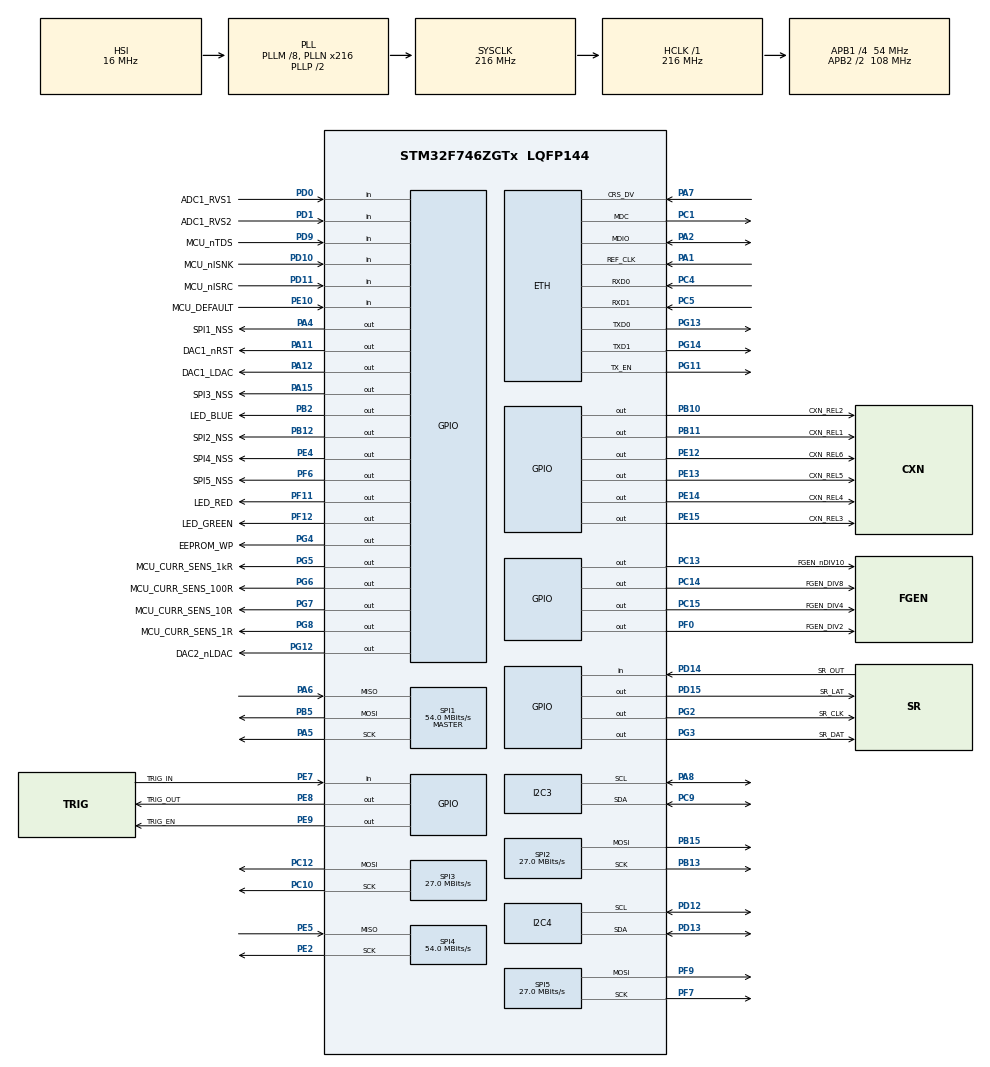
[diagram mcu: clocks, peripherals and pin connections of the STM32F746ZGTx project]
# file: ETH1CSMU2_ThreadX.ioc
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CORTEX_M7.CPU_DCache=Enabled
CORTEX_M7.CPU_ICache=Enabled
Dma.Request0=SPI4_RX
Dma.SPI4_RX.0.Direction=DMA_PERIPH_TO_MEMORY
Dma.SPI4_RX.0.FIFOMode=DMA_FIFOMODE_DISABLE
Dma.SPI4_RX.0.Instance=DMA2_Stream0
Dma.SPI4_RX.0.MemDataAlignment=DMA_MDATAALIGN_HALFWORD
Dma.SPI4_RX.0.MemInc=DMA_MINC_ENABLE
Dma.SPI4_RX.0.Mode=DMA_NORMAL
Dma.SPI4_RX.0.PeriphDataAlignment=DMA_PDATAALIGN_HALFWORD
Dma.SPI4_RX.0.PeriphInc=DMA_PINC_DISABLE
Dma.SPI4_RX.0.Priority=DMA_PRIORITY_LOW
ETH.MediaInterface=HAL_ETH_RMII_MODE
ETH.RxMode=ETH_RXINTERRUPT_MODE
I2C3.Timing=0x20404768
I2C4.Timing=0x20404768
Mcu.Family=STM32F7
Mcu.Name=STM32F746ZGTx
Mcu.Package=LQFP144
NVIC.DMA2_Stream0_IRQn=true\:0\:0\:false\:false\:true\:true\:false\:true\:true
NVIC.ETH_IRQn=true\:7\:0\:true\:false\:true\:false\:true\:true\:true
NVIC.PriorityGroup=NVIC_PRIORITYGROUP_4
NVIC.TIM1_UP_TIM10_IRQn=true\:15\:0\:false\:false\:true\:false\:false\:true\:true
NVIC.TimeBase=TIM1_UP_TIM10_IRQn
NVIC.TimeBaseIP=TIM1
PA1.Mode=RMII
PA1.Signal=ETH_REF_CLK
PA11.GPIO_Label=DAC1_nRST
PA11.PinState=GPIO_PIN_SET
PA11.Signal=GPIO_Output
PA12.GPIO_Label=DAC1_LDAC
PA12.Signal=GPIO_Output
PA13.Mode=Serial_Wire
PA13.Signal=SYS_JTMS-SWDIO
PA14.Mode=Serial_Wire
PA14.Signal=SYS_JTCK-SWCLK
PA15.GPIO_Label=SPI3_NSS
PA15.GPIO_Speed=GPIO_SPEED_FREQ_HIGH
PA15.PinState=GPIO_PIN_SET
PA15.Signal=GPIO_Output
PA2.Mode=RMII
PA2.Signal=ETH_MDIO
PA4.GPIO_Label=SPI1_NSS
PA4.GPIO_Speed=GPIO_SPEED_FREQ_HIGH
PA4.PinState=GPIO_PIN_SET
PA4.Signal=GPIO_Output
PA5.GPIO_Speed=GPIO_SPEED_FREQ_HIGH
PA5.Mode=Full_Duplex_Master
PA5.Signal=SPI1_SCK
PA6.GPIO_Speed=GPIO_SPEED_FREQ_HIGH
PA6.Mode=Full_Duplex_Master
PA6.Signal=SPI1_MISO
PA7.Mode=RMII
PA7.Signal=ETH_CRS_DV
PA8.Mode=I2C
PA8.Signal=I2C3_SCL
PB10.GPIO_Label=CXN_REL2
PB10.GPIO_Speed=GPIO_SPEED_FREQ_HIGH
PB10.Signal=GPIO_Output
PB11.GPIO_Label=CXN_REL1
PB11.GPIO_Speed=GPIO_SPEED_FREQ_HIGH
PB11.Signal=GPIO_Output
PB12.GPIO_Label=SPI2_NSS
PB12.GPIO_Speed=GPIO_SPEED_FREQ_HIGH
PB12.PinState=GPIO_PIN_SET
PB12.Signal=GPIO_Output
PB13.Mode=TX_Only_Simplex_Unidirect_Master
PB13.Signal=SPI2_SCK
PB15.Mode=TX_Only_Simplex_Unidirect_Master
PB15.Signal=SPI2_MOSI
PB2.GPIO_Label=LED_BLUE
PB2.PinState=GPIO_PIN_SET
PB2.Signal=GPIO_Output
PB5.GPIO_Speed=GPIO_SPEED_FREQ_HIGH
PB5.Mode=Full_Duplex_Master
PB5.Signal=SPI1_MOSI
PC1.Mode=RMII
PC1.Signal=ETH_MDC
PC10.GPIO_PuPd=GPIO_PULLUP
PC10.GPIO_Speed=GPIO_SPEED_FREQ_HIGH
PC10.Mode=TX_Only_Simplex_Unidirect_Master
PC10.Signal=SPI3_SCK
PC12.GPIO_PuPd=GPIO_NOPULL
PC12.GPIO_Speed=GPIO_SPEED_FREQ_HIGH
PC12.Mode=TX_Only_Simplex_Unidirect_Master
PC12.Signal=SPI3_MOSI
PC13.GPIO_Label=FGEN_nDIV10
PC13.PinState=GPIO_PIN_SET
PC13.Signal=GPIO_Output
PC14/OSC32_IN.GPIO_Label=FGEN_DIV8
PC14/OSC32_IN.PinState=GPIO_PIN_SET
PC14/OSC32_IN.Signal=GPIO_Output
PC15/OSC32_OUT.GPIO_Label=FGEN_DIV4
PC15/OSC32_OUT.PinState=GPIO_PIN_SET
PC15/OSC32_OUT.Signal=GPIO_Output
PC4.Mode=RMII
PC4.Signal=ETH_RXD0
PC5.Mode=RMII
PC5.Signal=ETH_RXD1
PC9.Mode=I2C
PC9.Signal=I2C3_SDA
PD0.GPIO_Label=ADC1_RVS1
PD0.Signal=GPIO_Input
PD1.GPIO_Label=ADC1_RVS2
PD1.Signal=GPIO_Input
PD10.GPIO_Label=MCU_nISNK
PD10.Signal=GPIO_Input
PD11.GPIO_Label=MCU_nISRC
PD11.Signal=GPIO_Input
PD12.Mode=I2C
PD12.Signal=I2C4_SCL
PD13.Mode=I2C
PD13.Signal=I2C4_SDA
PD14.GPIO_Label=SR_OUT
PD14.Signal=GPIO_Input
PD15.GPIO_Label=SR_LAT
PD15.Signal=GPIO_Output
PD9.GPIO_Label=MCU_nTDS
PD9.Signal=GPIO_Input
PE10.GPIO_Label=MCU_DEFAULT
PE10.Signal=GPIO_Input
PE12.GPIO_Label=CXN_REL6
PE12.GPIO_Speed=GPIO_SPEED_FREQ_HIGH
PE12.Signal=GPIO_Output
PE13.GPIO_Label=CXN_REL5
PE13.GPIO_Speed=GPIO_SPEED_FREQ_HIGH
PE13.Signal=GPIO_Output
PE14.GPIO_Label=CXN_REL4
PE14.GPIO_Speed=GPIO_SPEED_FREQ_HIGH
PE14.Signal=GPIO_Output
PE15.GPIO_Label=CXN_REL3
PE15.GPIO_Speed=GPIO_SPEED_FREQ_HIGH
PE15.Signal=GPIO_Output
PE2.Mode=RX_Only_Simplex_Unidirect_Master
PE2.Signal=SPI4_SCK
PE4.GPIO_Label=SPI4_NSS
PE4.Signal=GPIO_Output
PE5.Mode=RX_Only_Simplex_Unidirect_Master
PE5.Signal=SPI4_MISO
PE7.GPIO_Label=TRIG_IN
PE7.Signal=GPIO_Input
PE8.GPIO_Label=TRIG_OUT
PE8.Signal=GPIO_Output
PE9.GPIO_Label=TRIG_EN
PE9.Signal=GPIO_Output
PF0.GPIO_Label=FGEN_DIV2
PF0.PinState=GPIO_PIN_SET
PF0.Signal=GPIO_Output
PF11.GPIO_Label=LED_RED
PF11.PinState=GPIO_PIN_SET
PF11.Signal=GPIO_Output
PF12.GPIO_Label=LED_GREEN
PF12.PinState=GPIO_PIN_SET
PF12.Signal=GPIO_Output
PF6.GPIO_Label=SPI5_NSS
PF6.GPIO_Speed=GPIO_SPEED_FREQ_HIGH
PF6.PinState=GPIO_PIN_SET
PF6.Signal=GPIO_Output
PF7.Mode=TX_Only_Simplex_Unidirect_Master
PF7.Signal=SPI5_SCK
PF9.Mode=TX_Only_Simplex_Unidirect_Master
PF9.Signal=SPI5_MOSI
PG11.Mode=RMII
PG11.Signal=ETH_TX_EN
PG12.GPIO_Label=DAC2_nLDAC
PG12.PinState=GPIO_PIN_SET
PG12.Signal=GPIO_Output
PG13.Mode=RMII
PG13.Signal=ETH_TXD0
PG14.Mode=RMII
PG14.Signal=ETH_TXD1
PG2.GPIO_Label=SR_CLK
PG2.Signal=GPIO_Output
PG3.GPIO_Label=SR_DAT
PG3.Signal=GPIO_Output
PG4.GPIO_Label=EEPROM_WP
PG4.PinState=GPIO_PIN_SET
PG4.Signal=GPIO_Output
PG5.GPIO_Label=MCU_CURR_SENS_1kR
PG5.Signal=GPIO_Output
PG6.GPIO_Label=MCU_CURR_SENS_100R
PG6.PinState=GPIO_PIN_SET
PG6.Signal=GPIO_Output
PG7.GPIO_Label=MCU_CURR_SENS_10R
PG7.Signal=GPIO_Output
PG8.GPIO_Label=MCU_CURR_SENS_1R
PG8.Signal=GPIO_Output
ProjectManager.HeapSize=0x200
ProjectManager.StackSize=0x400
ProjectManager.TargetToolchain=STM32CubeIDE
RCC.AHBFreq_Value=216000000
RCC.APB1CLKDivider=RCC_HCLK_DIV4
RCC.APB1Freq_Value=54000000
RCC.APB1TimFreq_Value=108000000
RCC.APB2CLKDivider=RCC_HCLK_DIV2
RCC.APB2Freq_Value=108000000
RCC.APB2TimFreq_Value=216000000
RCC.CortexFreq_Value=216000000
RCC.HCLKFreq_Value=216000000
RCC.HSE_VALUE=25000000
RCC.HSI_VALUE=16000000
RCC.LSE_VALUE=32768
RCC.PLLM=8
RCC.PLLN=216
RCC.SYSCLKFreq_VALUE=216000000
RCC.SYSCLKSource=RCC_SYSCLKSOURCE_PLLCLK
RCC.USBFreq_Value=216000000
RCC.VCOOutputFreq_Value=432000000
SPI1.CalculateBaudRate=54.0 MBits/s
SPI1.DataSize=SPI_DATASIZE_16BIT
SPI1.Direction=SPI_DIRECTION_2LINES
SPI1.Mode=SPI_MODE_MASTER
SPI1.VirtualType=VM_MASTER
SPI2.CLKPolarity=SPI_POLARITY_HIGH
SPI2.CalculateBaudRate=27.0 MBits/s
SPI2.DataSize=SPI_DATASIZE_8BIT
SPI2.Direction=SPI_DIRECTION_2LINES
SPI2.Mode=SPI_MODE_MASTER
SPI2.VirtualType=VM_MASTER
SPI3.CLKPolarity=SPI_POLARITY_HIGH
SPI3.CalculateBaudRate=27.0 MBits/s
SPI3.DataSize=SPI_DATASIZE_16BIT
SPI3.Direction=SPI_DIRECTION_2LINES
SPI3.Mode=SPI_MODE_MASTER
SPI3.VirtualType=VM_MASTER
SPI4.CalculateBaudRate=54.0 MBits/s
SPI4.DataSize=SPI_DATASIZE_16BIT
SPI4.Direction=SPI_DIRECTION_2LINES_RXONLY
SPI4.Mode=SPI_MODE_MASTER
SPI4.VirtualType=VM_MASTER
SPI5.BaudRatePrescaler=SPI_BAUDRATEPRESCALER_4
SPI5.CalculateBaudRate=27.0 MBits/s
SPI5.DataSize=SPI_DATASIZE_16BIT
SPI5.Direction=SPI_DIRECTION_2LINES
SPI5.Mode=SPI_MODE_MASTER
SPI5.VirtualType=VM_MASTER
STMicroelectronics.X-CUBE-AZRTOS-F7.1.1.0.InterfacesCcNetworkJjEthernetOoInterface=true
STMicroelectronics.X-CUBE-AZRTOS-F7.1.1.0.InterfacesCcNetworkJjEthernetOoPhyOoInterface=LAN8742IiPhyIiInterface
STMicroelectronics.X-CUBE-AZRTOS-F7.1.1.0.NX_APP_MEM_POOL_SIZE=1024*30
STMicroelectronics.X-CUBE-AZRTOS-F7.1.1.0.NetXDuoCcNetworkJjNetXDuoJjAddonsOoAutoIP=true
STMicroelectronics.X-CUBE-AZRTOS-F7.1.1.0.NetXDuoCcNetworkJjNetXDuoJjAddonsOoPPP=true
STMicroelectronics.X-CUBE-AZRTOS-F7.1.1.0.NetXDuoCcNetworkJjNetXDuoJjAddonsOoSNTP=true
STMicroelectronics.X-CUBE-AZRTOS-F7.1.1.0.NetXDuoCcNetworkJjNetXDuoJjNXOoCore=true
STMicroelectronics.X-CUBE-AZRTOS-F7.1.1.0.NetXDuoCcNetworkJjNetXDuoJjTraceXOoSupport=true
STMicroelectronics.X-CUBE-AZRTOS-F7.1.1.0.STM32CubeIiBSPIiComponentsCcBoardOoPartJjETHPhyJjLAN8742=true
STMicroelectronics.X-CUBE-AZRTOS-F7.1.1.0.TX_APP_MEM_POOL_SIZE=1024*2
STMicroelectronics.X-CUBE-AZRTOS-F7.1.1.0.TX_TIMER_TICKS_PER_SECOND=1000
STMicroelectronics.X-CUBE-AZRTOS-F7.1.1.0.ThreadXCcRTOSJjThreadXJjCore=true
STMicroelectronics.X-CUBE-AZRTOS-F7.1.1.0.ThreadXCcRTOSJjThreadXJjLowOoPowerOosupport=true
STMicroelectronics.X-CUBE-AZRTOS-F7.1.1.0.ThreadXCcRTOSJjThreadXJjPerformanceInfo=true
STMicroelectronics.X-CUBE-AZRTOS-F7.1.1.0.ThreadXCcRTOSJjThreadXJjTraceXOosupport=true
STMicroelectronics.X-CUBE-AZRTOS-F7.1.1.0_IsAnAzureRtosMw=true
VP_STMicroelectronics.X-CUBE-AZRTOS-F7_VS_BoardOoPartJjSTM32CubeIiBSPIiComponents_1.1.0_1.1.0.Mode=BoardOoPartJjSTM32CubeIiBSPIiComponents
VP_STMicroelectronics.X-CUBE-AZRTOS-F7_VS_NetworkJjInterfaces_2.1.0_1.1.0.Mode=NetworkJjInterfaces
VP_STMicroelectronics.X-CUBE-AZRTOS-F7_VS_NetworkJjNetXDuo_6.1.10_1.1.0.Mode=NetworkJjNetXDuo
VP_STMicroelectronics.X-CUBE-AZRTOS-F7_VS_RTOSJjThreadX_6.1.10_1.1.0.Mode=RTOSJjThreadX
VP_SYS_VS_tim1.Mode=TIM1
board=custom

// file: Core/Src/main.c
/* USER CODE BEGIN Header */
/**
  ******************************************************************************
  * @file           : main.c
  * @brief          : Main program body
  ******************************************************************************
  * @attention
  *
  * Copyright (c) 2023 STMicroelectronics.
  * All rights reserved.
  *
  * This software is licensed under terms that can be found in the LICENSE file
  * in the root directory of this software component.
  * If no LICENSE file comes with this software, it is provided AS-IS.
  *
  ******************************************************************************
  */
/* USER CODE END Header */
#include "app_threadx.h"
#include "main.h"
#include "string.h"

/* USER CODE BEGIN Includes */
#include "DWT_Delay.h"
#include "74HC595.h"
#include "AD9834.h"
#include "MAX5217.h"
#include "DAC8565.h"
#include "ADS8681.h"
#include "FGEN.h"
/* USER CODE END Includes */

#if defined ( __ICCARM__ ) /*!< IAR Compiler */
#pragma location=0x2004c000
ETH_DMADescTypeDef  DMARxDscrTab[ETH_RX_DESC_CNT]; /* Ethernet Rx DMA Descriptors */
#pragma location=0x2004c0a0
ETH_DMADescTypeDef  DMATxDscrTab[ETH_TX_DESC_CNT]; /* Ethernet Tx DMA Descriptors */

#elif defined ( __CC_ARM )  /* MDK ARM Compiler */

__attribute__((at(0x2004c000))) ETH_DMADescTypeDef  DMARxDscrTab[ETH_RX_DESC_CNT]; /* Ethernet Rx DMA Descriptors */
__attribute__((at(0x2004c0a0))) ETH_DMADescTypeDef  DMATxDscrTab[ETH_TX_DESC_CNT]; /* Ethernet Tx DMA Descriptors */

#elif defined ( __GNUC__ ) /* GNU Compiler */
ETH_DMADescTypeDef DMARxDscrTab[ETH_RX_DESC_CNT] __attribute__((section(".RxDecripSection"))); /* Ethernet Rx DMA Descriptors */
ETH_DMADescTypeDef DMATxDscrTab[ETH_TX_DESC_CNT] __attribute__((section(".TxDecripSection")));   /* Ethernet Tx DMA Descriptors */

#endif

ETH_TxPacketConfig TxConfig;

ETH_HandleTypeDef heth;

I2C_HandleTypeDef hi2c3;
I2C_HandleTypeDef hi2c4;

SPI_HandleTypeDef hspi1;
SPI_HandleTypeDef hspi2;
SPI_HandleTypeDef hspi3;
SPI_HandleTypeDef hspi4;
SPI_HandleTypeDef hspi5;
DMA_HandleTypeDef hdma_spi4_rx;

void SystemClock_Config(void);
static void MX_GPIO_Init(void);
static void MX_DMA_Init(void);
static void MX_I2C3_Init(void);
static void MX_I2C4_Init(void);
static void MX_SPI1_Init(void);
static void MX_SPI2_Init(void);
static void MX_SPI3_Init(void);
static void MX_SPI4_Init(void);
static void MX_ETH_Init(void);
static void MX_SPI5_Init(void);

int main(void)
{

  /* Enable I-Cache---------------------------------------------------------*/
  SCB_EnableICache();

  /* Enable D-Cache---------------------------------------------------------*/
  SCB_EnableDCache();

  /* MCU Configuration--------------------------------------------------------*/

  /* Reset of all peripherals, Initializes the Flash interface and the Systick. */
  HAL_Init();

  /* Configure the system clock */
  SystemClock_Config();

  /* Initialize all configured peripherals */
  MX_GPIO_Init();
  MX_DMA_Init();
  MX_I2C3_Init();
  MX_I2C4_Init();
  MX_SPI1_Init();
  MX_SPI2_Init();
  MX_SPI3_Init();
  MX_SPI4_Init();
  MX_ETH_Init();
  MX_SPI5_Init();
  /* USER CODE BEGIN 2 */
  DAC8565_Init();
  DWT_Init();
  BSP_Init();
  SN74HC595_Init();
  MAX5217_Init();
  ADS8681_Init();
  FGEN_Init();
  /* USER CODE END 2 */

  MX_ThreadX_Init();

  /* We should never get here as control is now taken by the scheduler */
  /* Infinite loop */
  while (1)
  {

  }
}

void SystemClock_Config(void)
{
  RCC_OscInitTypeDef RCC_OscInitStruct = {0};
  RCC_ClkInitTypeDef RCC_ClkInitStruct = {0};

  /** Configure the main internal regulator output voltage
  */
  __HAL_RCC_PWR_CLK_ENABLE();
  __HAL_PWR_VOLTAGESCALING_CONFIG(PWR_REGULATOR_VOLTAGE_SCALE1);

  /** Initializes the RCC Oscillators according to the specified parameters
  * in the RCC_OscInitTypeDef structure.
  */
  RCC_OscInitStruct.OscillatorType = RCC_OSCILLATORTYPE_HSI;
  RCC_OscInitStruct.HSIState = RCC_HSI_ON;
  RCC_OscInitStruct.HSICalibrationValue = RCC_HSICALIBRATION_DEFAULT;
  RCC_OscInitStruct.PLL.PLLState = RCC_PLL_ON;
  RCC_OscInitStruct.PLL.PLLSource = RCC_PLLSOURCE_HSI;
  RCC_OscInitStruct.PLL.PLLM = 8;
  RCC_OscInitStruct.PLL.PLLN = 216;
  RCC_OscInitStruct.PLL.PLLP = RCC_PLLP_DIV2;
  RCC_OscInitStruct.PLL.PLLQ = 2;
  if (HAL_RCC_OscConfig(&RCC_OscInitStruct) != HAL_OK)
  {
    Error_Handler();
  }

  /** Activate the Over-Drive mode
  */
  if (HAL_PWREx_EnableOverDrive() != HAL_OK)
  {
    Error_Handler();
  }

  /** Initializes the CPU, AHB and APB buses clocks
  */
  RCC_ClkInitStruct.ClockType = RCC_CLOCKTYPE_HCLK|RCC_CLOCKTYPE_SYSCLK
                              |RCC_CLOCKTYPE_PCLK1|RCC_CLOCKTYPE_PCLK2;
  RCC_ClkInitStruct.SYSCLKSource = RCC_SYSCLKSOURCE_PLLCLK;
  RCC_ClkInitStruct.AHBCLKDivider = RCC_SYSCLK_DIV1;
  RCC_ClkInitStruct.APB1CLKDivider = RCC_HCLK_DIV4;
  RCC_ClkInitStruct.APB2CLKDivider = RCC_HCLK_DIV2;

  if (HAL_RCC_ClockConfig(&RCC_ClkInitStruct, FLASH_LATENCY_7) != HAL_OK)
  {
    Error_Handler();
  }
}

static void MX_ETH_Init(void)
{

   static uint8_t MACAddr[6];

  heth.Instance = ETH;
  MACAddr[0] = 0x00;
  MACAddr[1] = 0x80;
  MACAddr[2] = 0xE1;
  MACAddr[3] = 0x00;
  MACAddr[4] = 0x00;
  MACAddr[5] = 0x00;
  heth.Init.MACAddr = &MACAddr[0];
  heth.Init.MediaInterface = HAL_ETH_RMII_MODE;
  heth.Init.TxDesc = DMATxDscrTab;
  heth.Init.RxDesc = DMARxDscrTab;
  heth.Init.RxBuffLen = 1536;

  if (HAL_ETH_Init(&heth) != HAL_OK)
  {
    Error_Handler();
  }

  memset(&TxConfig, 0 , sizeof(ETH_TxPacketConfig));
  TxConfig.Attributes = ETH_TX_PACKETS_FEATURES_CSUM | ETH_TX_PACKETS_FEATURES_CRCPAD;
  TxConfig.ChecksumCtrl = ETH_CHECKSUM_IPHDR_PAYLOAD_INSERT_PHDR_CALC;
  TxConfig.CRCPadCtrl = ETH_CRC_PAD_INSERT;

}

static void MX_I2C3_Init(void)
{

  hi2c3.Instance = I2C3;
  hi2c3.Init.Timing = 0x20404768;
  hi2c3.Init.OwnAddress1 = 0;
  hi2c3.Init.AddressingMode = I2C_ADDRESSINGMODE_7BIT;
  hi2c3.Init.DualAddressMode = I2C_DUALADDRESS_DISABLE;
  hi2c3.Init.OwnAddress2 = 0;
  hi2c3.Init.OwnAddress2Masks = I2C_OA2_NOMASK;
  hi2c3.Init.GeneralCallMode = I2C_GENERALCALL_DISABLE;
  hi2c3.Init.NoStretchMode = I2C_NOSTRETCH_DISABLE;
  if (HAL_I2C_Init(&hi2c3) != HAL_OK)
  {
    Error_Handler();
  }

  /** Configure Analogue filter
  */
  if (HAL_I2CEx_ConfigAnalogFilter(&hi2c3, I2C_ANALOGFILTER_ENABLE) != HAL_OK)
  {
    Error_Handler();
  }

  /** Configure Digital filter
  */
  if (HAL_I2CEx_ConfigDigitalFilter(&hi2c3, 0) != HAL_OK)
  {
    Error_Handler();
  }

}

static void MX_I2C4_Init(void)
{

  hi2c4.Instance = I2C4;
  hi2c4.Init.Timing = 0x20404768;
  hi2c4.Init.OwnAddress1 = 0;
  hi2c4.Init.AddressingMode = I2C_ADDRESSINGMODE_7BIT;
  hi2c4.Init.DualAddressMode = I2C_DUALADDRESS_DISABLE;
  hi2c4.Init.OwnAddress2 = 0;
  hi2c4.Init.OwnAddress2Masks = I2C_OA2_NOMASK;
  hi2c4.Init.GeneralCallMode = I2C_GENERALCALL_DISABLE;
  hi2c4.Init.NoStretchMode = I2C_NOSTRETCH_DISABLE;
  if (HAL_I2C_Init(&hi2c4) != HAL_OK)
  {
    Error_Handler();
  }

  /** Configure Analogue filter
  */
  if (HAL_I2CEx_ConfigAnalogFilter(&hi2c4, I2C_ANALOGFILTER_ENABLE) != HAL_OK)
  {
    Error_Handler();
  }

  /** Configure Digital filter
  */
  if (HAL_I2CEx_ConfigDigitalFilter(&hi2c4, 0) != HAL_OK)
  {
    Error_Handler();
  }

}

static void MX_SPI1_Init(void)
{

  /* SPI1 parameter configuration*/
  hspi1.Instance = SPI1;
  hspi1.Init.Mode = SPI_MODE_MASTER;
  hspi1.Init.Direction = SPI_DIRECTION_2LINES;
  hspi1.Init.DataSize = SPI_DATASIZE_16BIT;
  hspi1.Init.CLKPolarity = SPI_POLARITY_LOW;
  hspi1.Init.CLKPhase = SPI_PHASE_1EDGE;
  hspi1.Init.NSS = SPI_NSS_SOFT;
  hspi1.Init.BaudRatePrescaler = SPI_BAUDRATEPRESCALER_2;
  hspi1.Init.FirstBit = SPI_FIRSTBIT_MSB;
  hspi1.Init.TIMode = SPI_TIMODE_DISABLE;
  hspi1.Init.CRCCalculation = SPI_CRCCALCULATION_DISABLE;
  hspi1.Init.CRCPolynomial = 7;
  hspi1.Init.CRCLength = SPI_CRC_LENGTH_DATASIZE;
  hspi1.Init.NSSPMode = SPI_NSS_PULSE_ENABLE;
  if (HAL_SPI_Init(&hspi1) != HAL_OK)
  {
    Error_Handler();
  }

}

static void MX_SPI2_Init(void)
{

  /* SPI2 parameter configuration*/
  hspi2.Instance = SPI2;
  hspi2.Init.Mode = SPI_MODE_MASTER;
  hspi2.Init.Direction = SPI_DIRECTION_2LINES;
  hspi2.Init.DataSize = SPI_DATASIZE_8BIT;
  hspi2.Init.CLKPolarity = SPI_POLARITY_HIGH;
  hspi2.Init.CLKPhase = SPI_PHASE_1EDGE;
  hspi2.Init.NSS = SPI_NSS_SOFT;
  hspi2.Init.BaudRatePrescaler = SPI_BAUDRATEPRESCALER_2;
  hspi2.Init.FirstBit = SPI_FIRSTBIT_MSB;
  hspi2.Init.TIMode = SPI_TIMODE_DISABLE;
  hspi2.Init.CRCCalculation = SPI_CRCCALCULATION_DISABLE;
  hspi2.Init.CRCPolynomial = 7;
  hspi2.Init.CRCLength = SPI_CRC_LENGTH_DATASIZE;
  hspi2.Init.NSSPMode = SPI_NSS_PULSE_ENABLE;
  if (HAL_SPI_Init(&hspi2) != HAL_OK)
  {
    Error_Handler();
  }

}

static void MX_SPI3_Init(void)
{

  /* SPI3 parameter configuration*/
  hspi3.Instance = SPI3;
  hspi3.Init.Mode = SPI_MODE_MASTER;
  hspi3.Init.Direction = SPI_DIRECTION_2LINES;
  hspi3.Init.DataSize = SPI_DATASIZE_16BIT;
  hspi3.Init.CLKPolarity = SPI_POLARITY_HIGH;
  hspi3.Init.CLKPhase = SPI_PHASE_1EDGE;
  hspi3.Init.NSS = SPI_NSS_SOFT;
  hspi3.Init.BaudRatePrescaler = SPI_BAUDRATEPRESCALER_2;
  hspi3.Init.FirstBit = SPI_FIRSTBIT_MSB;
  hspi3.Init.TIMode = SPI_TIMODE_DISABLE;
  hspi3.Init.CRCCalculation = SPI_CRCCALCULATION_DISABLE;
  hspi3.Init.CRCPolynomial = 7;
  hspi3.Init.CRCLength = SPI_CRC_LENGTH_DATASIZE;
  hspi3.Init.NSSPMode = SPI_NSS_PULSE_ENABLE;
  if (HAL_SPI_Init(&hspi3) != HAL_OK)
  {
    Error_Handler();
  }

}

static void MX_SPI4_Init(void)
{

  /* SPI4 parameter configuration*/
  hspi4.Instance = SPI4;
  hspi4.Init.Mode = SPI_MODE_MASTER;
  hspi4.Init.Direction = SPI_DIRECTION_2LINES_RXONLY;
  hspi4.Init.DataSize = SPI_DATASIZE_16BIT;
  hspi4.Init.CLKPolarity = SPI_POLARITY_LOW;
  hspi4.Init.CLKPhase = SPI_PHASE_1EDGE;
  hspi4.Init.NSS = SPI_NSS_SOFT;
  hspi4.Init.BaudRatePrescaler = SPI_BAUDRATEPRESCALER_2;
  hspi4.Init.FirstBit = SPI_FIRSTBIT_MSB;
  hspi4.Init.TIMode = SPI_TIMODE_DISABLE;
  hspi4.Init.CRCCalculation = SPI_CRCCALCULATION_DISABLE;
  hspi4.Init.CRCPolynomial = 7;
  hspi4.Init.CRCLength = SPI_CRC_LENGTH_DATASIZE;
  hspi4.Init.NSSPMode = SPI_NSS_PULSE_ENABLE;
  if (HAL_SPI_Init(&hspi4) != HAL_OK)
  {
    Error_Handler();
  }

}

static void MX_SPI5_Init(void)
{

  /* SPI5 parameter configuration*/
  hspi5.Instance = SPI5;
  hspi5.Init.Mode = SPI_MODE_MASTER;
  hspi5.Init.Direction = SPI_DIRECTION_2LINES;
  hspi5.Init.DataSize = SPI_DATASIZE_16BIT;
  hspi5.Init.CLKPolarity = SPI_POLARITY_LOW;
  hspi5.Init.CLKPhase = SPI_PHASE_1EDGE;
  hspi5.Init.NSS = SPI_NSS_SOFT;
  hspi5.Init.BaudRatePrescaler = SPI_BAUDRATEPRESCALER_4;
  hspi5.Init.FirstBit = SPI_FIRSTBIT_MSB;
  hspi5.Init.TIMode = SPI_TIMODE_DISABLE;
  hspi5.Init.CRCCalculation = SPI_CRCCALCULATION_DISABLE;
  hspi5.Init.CRCPolynomial = 7;
  hspi5.Init.CRCLength = SPI_CRC_LENGTH_DATASIZE;
  hspi5.Init.NSSPMode = SPI_NSS_PULSE_ENABLE;
  if (HAL_SPI_Init(&hspi5) != HAL_OK)
  {
    Error_Handler();
  }

}

static void MX_DMA_Init(void)
{

  /* DMA controller clock enable */
  __HAL_RCC_DMA2_CLK_ENABLE();

  /* DMA interrupt init */
  /* DMA2_Stream0_IRQn interrupt configuration */
  HAL_NVIC_SetPriority(DMA2_Stream0_IRQn, 0, 0);
  HAL_NVIC_EnableIRQ(DMA2_Stream0_IRQn);

}

static void MX_GPIO_Init(void)
{
  LL_GPIO_InitTypeDef GPIO_InitStruct = {0};

  /* GPIO Ports Clock Enable */
  LL_AHB1_GRP1_EnableClock(LL_AHB1_GRP1_PERIPH_GPIOE);
  LL_AHB1_GRP1_EnableClock(LL_AHB1_GRP1_PERIPH_GPIOC);
  LL_AHB1_GRP1_EnableClock(LL_AHB1_GRP1_PERIPH_GPIOF);
  LL_AHB1_GRP1_EnableClock(LL_AHB1_GRP1_PERIPH_GPIOA);
  LL_AHB1_GRP1_EnableClock(LL_AHB1_GRP1_PERIPH_GPIOB);
  LL_AHB1_GRP1_EnableClock(LL_AHB1_GRP1_PERIPH_GPIOD);
  LL_AHB1_GRP1_EnableClock(LL_AHB1_GRP1_PERIPH_GPIOG);

  /**/
  LL_GPIO_ResetOutputPin(SPI4_NSS_GPIO_Port, SPI4_NSS_Pin);

  /**/
  LL_GPIO_ResetOutputPin(TRIG_OUT_GPIO_Port, TRIG_OUT_Pin);

  /**/
  LL_GPIO_ResetOutputPin(TRIG_EN_GPIO_Port, TRIG_EN_Pin);

  /**/
  LL_GPIO_ResetOutputPin(CXN_REL6_GPIO_Port, CXN_REL6_Pin);

  /**/
  LL_GPIO_ResetOutputPin(CXN_REL5_GPIO_Port, CXN_REL5_Pin);

  /**/
  LL_GPIO_ResetOutputPin(CXN_REL4_GPIO_Port, CXN_REL4_Pin);

  /**/
  LL_GPIO_ResetOutputPin(CXN_REL3_GPIO_Port, CXN_REL3_Pin);

  /**/
  LL_GPIO_ResetOutputPin(CXN_REL2_GPIO_Port, CXN_REL2_Pin);

  /**/
  LL_GPIO_ResetOutputPin(CXN_REL1_GPIO_Port, CXN_REL1_Pin);

  /**/
  LL_GPIO_ResetOutputPin(SR_LAT_GPIO_Port, SR_LAT_Pin);

  /**/
  LL_GPIO_ResetOutputPin(SR_CLK_GPIO_Port, SR_CLK_Pin);

  /**/
  LL_GPIO_ResetOutputPin(SR_DAT_GPIO_Port, SR_DAT_Pin);

  /**/
  LL_GPIO_ResetOutputPin(MCU_CURR_SENS_1kR_GPIO_Port, MCU_CURR_SENS_1kR_Pin);

  /**/
  LL_GPIO_ResetOutputPin(MCU_CURR_SENS_10R_GPIO_Port, MCU_CURR_SENS_10R_Pin);

  /**/
  LL_GPIO_ResetOutputPin(MCU_CURR_SENS_1R_GPIO_Port, MCU_CURR_SENS_1R_Pin);

  /**/
  LL_GPIO_ResetOutputPin(DAC1_LDAC_GPIO_Port, DAC1_LDAC_Pin);

  /**/
  LL_GPIO_SetOutputPin(FGEN_nDIV10_GPIO_Port, FGEN_nDIV10_Pin);

  /**/
  LL_GPIO_SetOutputPin(FGEN_DIV8_GPIO_Port, FGEN_DIV8_Pin);

  /**/
  LL_GPIO_SetOutputPin(FGEN_DIV4_GPIO_Port, FGEN_DIV4_Pin);

  /**/
  LL_GPIO_SetOutputPin(FGEN_DIV2_GPIO_Port, FGEN_DIV2_Pin);

  /**/
  LL_GPIO_SetOutputPin(SPI5_NSS_GPIO_Port, SPI5_NSS_Pin);

  /**/
  LL_GPIO_SetOutputPin(SPI1_NSS_GPIO_Port, SPI1_NSS_Pin);

  /**/
  LL_GPIO_SetOutputPin(LED_BLUE_GPIO_Port, LED_BLUE_Pin);

  /**/
  LL_GPIO_SetOutputPin(LED_RED_GPIO_Port, LED_RED_Pin);

  /**/
  LL_GPIO_SetOutputPin(LED_GREEN_GPIO_Port, LED_GREEN_Pin);

  /**/
  LL_GPIO_SetOutputPin(SPI2_NSS_GPIO_Port, SPI2_NSS_Pin);

  /**/
  LL_GPIO_SetOutputPin(EEPROM_WP_GPIO_Port, EEPROM_WP_Pin);

  /**/
  LL_GPIO_SetOutputPin(MCU_CURR_SENS_100R_GPIO_Port, MCU_CURR_SENS_100R_Pin);

  /**/
  LL_GPIO_SetOutputPin(DAC1_nRST_GPIO_Port, DAC1_nRST_Pin);

  /**/
  LL_GPIO_SetOutputPin(SPI3_NSS_GPIO_Port, SPI3_NSS_Pin);

  /**/
  LL_GPIO_SetOutputPin(DAC2_nLDAC_GPIO_Port, DAC2_nLDAC_Pin);

  /**/
  GPIO_InitStruct.Pin = SPI4_NSS_Pin;
  GPIO_InitStruct.Mode = LL_GPIO_MODE_OUTPUT;
  GPIO_InitStruct.Speed = LL_GPIO_SPEED_FREQ_LOW;
  GPIO_InitStruct.OutputType = LL_GPIO_OUTPUT_PUSHPULL;
  GPIO_InitStruct.Pull = LL_GPIO_PULL_NO;
  LL_GPIO_Init(SPI4_NSS_GPIO_Port, &GPIO_InitStruct);

  /**/
  GPIO_InitStruct.Pin = FGEN_nDIV10_Pin;
  GPIO_InitStruct.Mode = LL_GPIO_MODE_OUTPUT;
  GPIO_InitStruct.Speed = LL_GPIO_SPEED_FREQ_LOW;
  GPIO_InitStruct.OutputType = LL_GPIO_OUTPUT_PUSHPULL;
  GPIO_InitStruct.Pull = LL_GPIO_PULL_NO;
  LL_GPIO_Init(FGEN_nDIV10_GPIO_Port, &GPIO_InitStruct);

  /**/
  GPIO_InitStruct.Pin = FGEN_DIV8_Pin;
  GPIO_InitStruct.Mode = LL_GPIO_MODE_OUTPUT;
  GPIO_InitStruct.Speed = LL_GPIO_SPEED_FREQ_LOW;
  GPIO_InitStruct.OutputType = LL_GPIO_OUTPUT_PUSHPULL;
  GPIO_InitStruct.Pull = LL_GPIO_PULL_NO;
  LL_GPIO_Init(FGEN_DIV8_GPIO_Port, &GPIO_InitStruct);

  /**/
  GPIO_InitStruct.Pin = FGEN_DIV4_Pin;
  GPIO_InitStruct.Mode = LL_GPIO_MODE_OUTPUT;
  GPIO_InitStruct.Speed = LL_GPIO_SPEED_FREQ_LOW;
  GPIO_InitStruct.OutputType = LL_GPIO_OUTPUT_PUSHPULL;
  GPIO_InitStruct.Pull = LL_GPIO_PULL_NO;
  LL_GPIO_Init(FGEN_DIV4_GPIO_Port, &GPIO_InitStruct);

  /**/
  GPIO_InitStruct.Pin = FGEN_DIV2_Pin;
  GPIO_InitStruct.Mode = LL_GPIO_MODE_OUTPUT;
  GPIO_InitStruct.Speed = LL_GPIO_SPEED_FREQ_LOW;
  GPIO_InitStruct.OutputType = LL_GPIO_OUTPUT_PUSHPULL;
  GPIO_InitStruct.Pull = LL_GPIO_PULL_NO;
  LL_GPIO_Init(FGEN_DIV2_GPIO_Port, &GPIO_InitStruct);

  /**/
  GPIO_InitStruct.Pin = SPI5_NSS_Pin;
  GPIO_InitStruct.Mode = LL_GPIO_MODE_OUTPUT;
  GPIO_InitStruct.Speed = LL_GPIO_SPEED_FREQ_HIGH;
  GPIO_InitStruct.OutputType = LL_GPIO_OUTPUT_PUSHPULL;
  GPIO_InitStruct.Pull = LL_GPIO_PULL_NO;
  LL_GPIO_Init(SPI5_NSS_GPIO_Port, &GPIO_InitStruct);

  /**/
  GPIO_InitStruct.Pin = SPI1_NSS_Pin;
  GPIO_InitStruct.Mode = LL_GPIO_MODE_OUTPUT;
  GPIO_InitStruct.Speed = LL_GPIO_SPEED_FREQ_HIGH;
  GPIO_InitStruct.OutputType = LL_GPIO_OUTPUT_PUSHPULL;
  GPIO_InitStruct.Pull = LL_GPIO_PULL_NO;
  LL_GPIO_Init(SPI1_NSS_GPIO_Port, &GPIO_InitStruct);

  /**/
  GPIO_InitStruct.Pin = LED_BLUE_Pin;
  GPIO_InitStruct.Mode = LL_GPIO_MODE_OUTPUT;
  GPIO_InitStruct.Speed = LL_GPIO_SPEED_FREQ_LOW;
  GPIO_InitStruct.OutputType = LL_GPIO_OUTPUT_PUSHPULL;
  GPIO_InitStruct.Pull = LL_GPIO_PULL_NO;
  LL_GPIO_Init(LED_BLUE_GPIO_Port, &GPIO_InitStruct);

  /**/
  GPIO_InitStruct.Pin = LED_RED_Pin;
  GPIO_InitStruct.Mode = LL_GPIO_MODE_OUTPUT;
  GPIO_InitStruct.Speed = LL_GPIO_SPEED_FREQ_LOW;
  GPIO_InitStruct.OutputType = LL_GPIO_OUTPUT_PUSHPULL;
  GPIO_InitStruct.Pull = LL_GPIO_PULL_NO;
  LL_GPIO_Init(LED_RED_GPIO_Port, &GPIO_InitStruct);

  /**/
  GPIO_InitStruct.Pin = LED_GREEN_Pin;
  GPIO_InitStruct.Mode = LL_GPIO_MODE_OUTPUT;
  GPIO_InitStruct.Speed = LL_GPIO_SPEED_FREQ_LOW;
  GPIO_InitStruct.OutputType = LL_GPIO_OUTPUT_PUSHPULL;
  GPIO_InitStruct.Pull = LL_GPIO_PULL_NO;
  LL_GPIO_Init(LED_GREEN_GPIO_Port, &GPIO_InitStruct);

  /**/
  GPIO_InitStruct.Pin = TRIG_IN_Pin;
  GPIO_InitStruct.Mode = LL_GPIO_MODE_INPUT;
  GPIO_InitStruct.Pull = LL_GPIO_PULL_NO;
  LL_GPIO_Init(TRIG_IN_GPIO_Port, &GPIO_InitStruct);

  /**/
  GPIO_InitStruct.Pin = TRIG_OUT_Pin;
  GPIO_InitStruct.Mode = LL_GPIO_MODE_OUTPUT;
  GPIO_InitStruct.Speed = LL_GPIO_SPEED_FREQ_LOW;
  GPIO_InitStruct.OutputType = LL_GPIO_OUTPUT_PUSHPULL;
  GPIO_InitStruct.Pull = LL_GPIO_PULL_NO;
  LL_GPIO_Init(TRIG_OUT_GPIO_Port, &GPIO_InitStruct);

  /**/
  GPIO_InitStruct.Pin = TRIG_EN_Pin;
  GPIO_InitStruct.Mode = LL_GPIO_MODE_OUTPUT;
  GPIO_InitStruct.Speed = LL_GPIO_SPEED_FREQ_LOW;
  GPIO_InitStruct.OutputType = LL_GPIO_OUTPUT_PUSHPULL;
  GPIO_InitStruct.Pull = LL_GPIO_PULL_NO;
  LL_GPIO_Init(TRIG_EN_GPIO_Port, &GPIO_InitStruct);

  /**/
  GPIO_InitStruct.Pin = MCU_DEFAULT_Pin;
  GPIO_InitStruct.Mode = LL_GPIO_MODE_INPUT;
  GPIO_InitStruct.Pull = LL_GPIO_PULL_NO;
  LL_GPIO_Init(MCU_DEFAULT_GPIO_Port, &GPIO_InitStruct);

  /**/
  GPIO_InitStruct.Pin = CXN_REL6_Pin;
  GPIO_InitStruct.Mode = LL_GPIO_MODE_OUTPUT;
  GPIO_InitStruct.Speed = LL_GPIO_SPEED_FREQ_HIGH;
  GPIO_InitStruct.OutputType = LL_GPIO_OUTPUT_PUSHPULL;
  GPIO_InitStruct.Pull = LL_GPIO_PULL_NO;
  LL_GPIO_Init(CXN_REL6_GPIO_Port, &GPIO_InitStruct);

  /**/
  GPIO_InitStruct.Pin = CXN_REL5_Pin;
  GPIO_InitStruct.Mode = LL_GPIO_MODE_OUTPUT;
  GPIO_InitStruct.Speed = LL_GPIO_SPEED_FREQ_HIGH;
  GPIO_InitStruct.OutputType = LL_GPIO_OUTPUT_PUSHPULL;
  GPIO_InitStruct.Pull = LL_GPIO_PULL_NO;
  LL_GPIO_Init(CXN_REL5_GPIO_Port, &GPIO_InitStruct);

  /**/
  GPIO_InitStruct.Pin = CXN_REL4_Pin;
  GPIO_InitStruct.Mode = LL_GPIO_MODE_OUTPUT;
  GPIO_InitStruct.Speed = LL_GPIO_SPEED_FREQ_HIGH;
  GPIO_InitStruct.OutputType = LL_GPIO_OUTPUT_PUSHPULL;
  GPIO_InitStruct.Pull = LL_GPIO_PULL_NO;
  LL_GPIO_Init(CXN_REL4_GPIO_Port, &GPIO_InitStruct);

  /**/
  GPIO_InitStruct.Pin = CXN_REL3_Pin;
  GPIO_InitStruct.Mode = LL_GPIO_MODE_OUTPUT;
  GPIO_InitStruct.Speed = LL_GPIO_SPEED_FREQ_HIGH;
  GPIO_InitStruct.OutputType = LL_GPIO_OUTPUT_PUSHPULL;
  GPIO_InitStruct.Pull = LL_GPIO_PULL_NO;
  LL_GPIO_Init(CXN_REL3_GPIO_Port, &GPIO_InitStruct);

  /**/
  GPIO_InitStruct.Pin = CXN_REL2_Pin;
  GPIO_InitStruct.Mode = LL_GPIO_MODE_OUTPUT;
  GPIO_InitStruct.Speed = LL_GPIO_SPEED_FREQ_HIGH;
  GPIO_InitStruct.OutputType = LL_GPIO_OUTPUT_PUSHPULL;
  GPIO_InitStruct.Pull = LL_GPIO_PULL_NO;
  LL_GPIO_Init(CXN_REL2_GPIO_Port, &GPIO_InitStruct);

  /**/
  GPIO_InitStruct.Pin = CXN_REL1_Pin;
  GPIO_InitStruct.Mode = LL_GPIO_MODE_OUTPUT;
  GPIO_InitStruct.Speed = LL_GPIO_SPEED_FREQ_HIGH;
  GPIO_InitStruct.OutputType = LL_GPIO_OUTPUT_PUSHPULL;
  GPIO_InitStruct.Pull = LL_GPIO_PULL_NO;
  LL_GPIO_Init(CXN_REL1_GPIO_Port, &GPIO_InitStruct);

  /**/
  GPIO_InitStruct.Pin = SPI2_NSS_Pin;
  GPIO_InitStruct.Mode = LL_GPIO_MODE_OUTPUT;
  GPIO_InitStruct.Speed = LL_GPIO_SPEED_FREQ_HIGH;
  GPIO_InitStruct.OutputType = LL_GPIO_OUTPUT_PUSHPULL;
  GPIO_InitStruct.Pull = LL_GPIO_PULL_NO;
  LL_GPIO_Init(SPI2_NSS_GPIO_Port, &GPIO_InitStruct);

  /**/
  GPIO_InitStruct.Pin = MCU_nTDS_Pin;
  GPIO_InitStruct.Mode = LL_GPIO_MODE_INPUT;
  GPIO_InitStruct.Pull = LL_GPIO_PULL_NO;
  LL_GPIO_Init(MCU_nTDS_GPIO_Port, &GPIO_InitStruct);

  /**/
  GPIO_InitStruct.Pin = MCU_nISNK_Pin;
  GPIO_InitStruct.Mode = LL_GPIO_MODE_INPUT;
  GPIO_InitStruct.Pull = LL_GPIO_PULL_NO;
  LL_GPIO_Init(MCU_nISNK_GPIO_Port, &GPIO_InitStruct);

  /**/
  GPIO_InitStruct.Pin = MCU_nISRC_Pin;
  GPIO_InitStruct.Mode = LL_GPIO_MODE_INPUT;
  GPIO_InitStruct.Pull = LL_GPIO_PULL_NO;
  LL_GPIO_Init(MCU_nISRC_GPIO_Port, &GPIO_InitStruct);

  /**/
  GPIO_InitStruct.Pin = SR_OUT_Pin;
  GPIO_InitStruct.Mode = LL_GPIO_MODE_INPUT;
  GPIO_InitStruct.Pull = LL_GPIO_PULL_NO;
  LL_GPIO_Init(SR_OUT_GPIO_Port, &GPIO_InitStruct);

  /**/
  GPIO_InitStruct.Pin = SR_LAT_Pin;
  GPIO_InitStruct.Mode = LL_GPIO_MODE_OUTPUT;
  GPIO_InitStruct.Speed = LL_GPIO_SPEED_FREQ_LOW;
  GPIO_InitStruct.OutputType = LL_GPIO_OUTPUT_PUSHPULL;
  GPIO_InitStruct.Pull = LL_GPIO_PULL_NO;
  LL_GPIO_Init(SR_LAT_GPIO_Port, &GPIO_InitStruct);

  /**/
  GPIO_InitStruct.Pin = SR_CLK_Pin;
  GPIO_InitStruct.Mode = LL_GPIO_MODE_OUTPUT;
  GPIO_InitStruct.Speed = LL_GPIO_SPEED_FREQ_LOW;
  GPIO_InitStruct.OutputType = LL_GPIO_OUTPUT_PUSHPULL;
  GPIO_InitStruct.Pull = LL_GPIO_PULL_NO;
  LL_GPIO_Init(SR_CLK_GPIO_Port, &GPIO_InitStruct);

  /**/
  GPIO_InitStruct.Pin = SR_DAT_Pin;
  GPIO_InitStruct.Mode = LL_GPIO_MODE_OUTPUT;
  GPIO_InitStruct.Speed = LL_GPIO_SPEED_FREQ_LOW;
  GPIO_InitStruct.OutputType = LL_GPIO_OUTPUT_PUSHPULL;
  GPIO_InitStruct.Pull = LL_GPIO_PULL_NO;
  LL_GPIO_Init(SR_DAT_GPIO_Port, &GPIO_InitStruct);

  /**/
  GPIO_InitStruct.Pin = EEPROM_WP_Pin;
  GPIO_InitStruct.Mode = LL_GPIO_MODE_OUTPUT;
  GPIO_InitStruct.Speed = LL_GPIO_SPEED_FREQ_LOW;
  GPIO_InitStruct.OutputType = LL_GPIO_OUTPUT_PUSHPULL;
  GPIO_InitStruct.Pull = LL_GPIO_PULL_NO;
  LL_GPIO_Init(EEPROM_WP_GPIO_Port, &GPIO_InitStruct);

  /**/
  GPIO_InitStruct.Pin = MCU_CURR_SENS_1kR_Pin;
  GPIO_InitStruct.Mode = LL_GPIO_MODE_OUTPUT;
  GPIO_InitStruct.Speed = LL_GPIO_SPEED_FREQ_LOW;
  GPIO_InitStruct.OutputType = LL_GPIO_OUTPUT_PUSHPULL;
  GPIO_InitStruct.Pull = LL_GPIO_PULL_NO;
  LL_GPIO_Init(MCU_CURR_SENS_1kR_GPIO_Port, &GPIO_InitStruct);

  /**/
  GPIO_InitStruct.Pin = MCU_CURR_SENS_100R_Pin;
  GPIO_InitStruct.Mode = LL_GPIO_MODE_OUTPUT;
  GPIO_InitStruct.Speed = LL_GPIO_SPEED_FREQ_LOW;
  GPIO_InitStruct.OutputType = LL_GPIO_OUTPUT_PUSHPULL;
  GPIO_InitStruct.Pull = LL_GPIO_PULL_NO;
  LL_GPIO_Init(MCU_CURR_SENS_100R_GPIO_Port, &GPIO_InitStruct);

  /**/
  GPIO_InitStruct.Pin = MCU_CURR_SENS_10R_Pin;
  GPIO_InitStruct.Mode = LL_GPIO_MODE_OUTPUT;
  GPIO_InitStruct.Speed = LL_GPIO_SPEED_FREQ_LOW;
  GPIO_InitStruct.OutputType = LL_GPIO_OUTPUT_PUSHPULL;
  GPIO_InitStruct.Pull = LL_GPIO_PULL_NO;
  LL_GPIO_Init(MCU_CURR_SENS_10R_GPIO_Port, &GPIO_InitStruct);

  /**/
  GPIO_InitStruct.Pin = MCU_CURR_SENS_1R_Pin;
  GPIO_InitStruct.Mode = LL_GPIO_MODE_OUTPUT;
  GPIO_InitStruct.Speed = LL_GPIO_SPEED_FREQ_LOW;
  GPIO_InitStruct.OutputType = LL_GPIO_OUTPUT_PUSHPULL;
  GPIO_InitStruct.Pull = LL_GPIO_PULL_NO;
  LL_GPIO_Init(MCU_CURR_SENS_1R_GPIO_Port, &GPIO_InitStruct);

  /**/
  GPIO_InitStruct.Pin = DAC1_nRST_Pin;
  GPIO_InitStruct.Mode = LL_GPIO_MODE_OUTPUT;
  GPIO_InitStruct.Speed = LL_GPIO_SPEED_FREQ_LOW;
  GPIO_InitStruct.OutputType = LL_GPIO_OUTPUT_PUSHPULL;
  GPIO_InitStruct.Pull = LL_GPIO_PULL_NO;
  LL_GPIO_Init(DAC1_nRST_GPIO_Port, &GPIO_InitStruct);

  /**/
  GPIO_InitStruct.Pin = DAC1_LDAC_Pin;
  GPIO_InitStruct.Mode = LL_GPIO_MODE_OUTPUT;
  GPIO_InitStruct.Speed = LL_GPIO_SPEED_FREQ_LOW;
  GPIO_InitStruct.OutputType = LL_GPIO_OUTPUT_PUSHPULL;
  GPIO_InitStruct.Pull = LL_GPIO_PULL_NO;
  LL_GPIO_Init(DAC1_LDAC_GPIO_Port, &GPIO_InitStruct);

  /**/
  GPIO_InitStruct.Pin = SPI3_NSS_Pin;
  GPIO_InitStruct.Mode = LL_GPIO_MODE_OUTPUT;
  GPIO_InitStruct.Speed = LL_GPIO_SPEED_FREQ_HIGH;
  GPIO_InitStruct.OutputType = LL_GPIO_OUTPUT_PUSHPULL;
  GPIO_InitStruct.Pull = LL_GPIO_PULL_NO;
  LL_GPIO_Init(SPI3_NSS_GPIO_Port, &GPIO_InitStruct);

  /**/
  GPIO_InitStruct.Pin = ADC1_RVS1_Pin;
  GPIO_InitStruct.Mode = LL_GPIO_MODE_INPUT;
  GPIO_InitStruct.Pull = LL_GPIO_PULL_NO;
  LL_GPIO_Init(ADC1_RVS1_GPIO_Port, &GPIO_InitStruct);

  /**/
  GPIO_InitStruct.Pin = ADC1_RVS2_Pin;
  GPIO_InitStruct.Mode = LL_GPIO_MODE_INPUT;
  GPIO_InitStruct.Pull = LL_GPIO_PULL_NO;
  LL_GPIO_Init(ADC1_RVS2_GPIO_Port, &GPIO_InitStruct);

  /**/
  GPIO_InitStruct.Pin = DAC2_nLDAC_Pin;
  GPIO_InitStruct.Mode = LL_GPIO_MODE_OUTPUT;
  GPIO_InitStruct.Speed = LL_GPIO_SPEED_FREQ_LOW;
  GPIO_InitStruct.OutputType = LL_GPIO_OUTPUT_PUSHPULL;
  GPIO_InitStruct.Pull = LL_GPIO_PULL_NO;
  LL_GPIO_Init(DAC2_nLDAC_GPIO_Port, &GPIO_InitStruct);

}

void HAL_TIM_PeriodElapsedCallback(TIM_HandleTypeDef *htim)
{
  if (htim->Instance == TIM1) {
    HAL_IncTick();
  }
}

void Error_Handler(void)
{
  __disable_irq();
  while (1)
  {
  }
}
